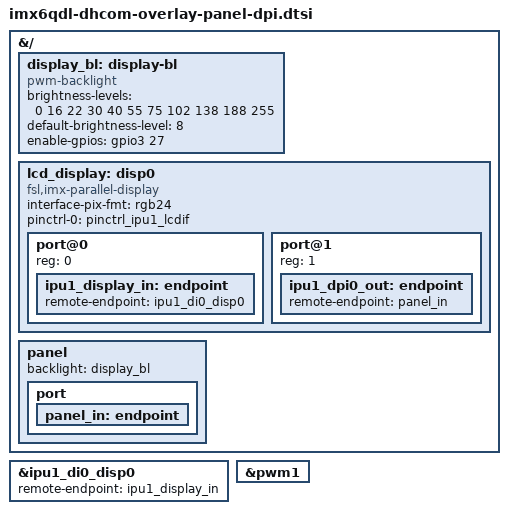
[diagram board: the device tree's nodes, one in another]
// SPDX-License-Identifier: (GPL-2.0+ OR BSD-3-Clause)
/*
 * Copyright (C) 2021-2026 Marek Vasut
 */
#include <dt-bindings/gpio/gpio.h>
#include <dt-bindings/input/input.h>
#include <dt-bindings/interrupt-controller/arm-gic.h>
#include <dt-bindings/pwm/pwm.h>

&{/} {
	display_bl: display-bl {
		compatible = "pwm-backlight";
		brightness-levels = <0 16 22 30 40 55 75 102 138 188 255>;
		default-brightness-level = <8>;
		enable-gpios = <&gpio3 27 GPIO_ACTIVE_HIGH>;
		status = "okay";
	};

	lcd_display: disp0 {
		compatible = "fsl,imx-parallel-display";
		#address-cells = <1>;
		#size-cells = <0>;
		interface-pix-fmt = "rgb24";
		pinctrl-names = "default";
		pinctrl-0 = <&pinctrl_ipu1_lcdif>;
		status = "okay";

		port@0 {
			reg = <0>;

			ipu1_display_in: endpoint {
				remote-endpoint = <&ipu1_di0_disp0>;
			};
		};

		port@1 {
			reg = <1>;

			ipu1_dpi0_out: endpoint {
				remote-endpoint = <&panel_in>;
			};
		};
	};

	panel: panel {
		backlight = <&display_bl>;

		port {
			panel_in: endpoint {
			};
		};
	};
};

&ipu1_di0_disp0 {
	remote-endpoint = <&ipu1_display_in>;
};

&pwm1 {
	status = "okay";
};
